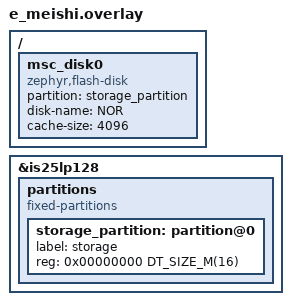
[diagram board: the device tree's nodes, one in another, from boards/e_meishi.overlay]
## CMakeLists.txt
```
cmake_minimum_required(VERSION 3.20.0)

find_package(Zephyr REQUIRED HINTS $ENV{ZEPHYR_BASE})
project(app)

target_sources(app PRIVATE
	src/main.c
	src/leds_pwm.c
	src/usb_msc.c
)
```

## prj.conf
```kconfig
CONFIG_MAIN_STACK_SIZE=2048

# Logging
CONFIG_LOG=y
CONFIG_USBD_LOG_LEVEL_WRN=y
CONFIG_UDC_DRIVER_LOG_LEVEL_WRN=y

# USB
CONFIG_USB_DEVICE_STACK_NEXT=y
CONFIG_USBD_MSC_CLASS=y
CONFIG_USBD_MSC_LUNS_PER_INSTANCE=1
# Serial number from the MCU unique ID (required by the MSC spec)
CONFIG_HWINFO=y

# Flash disk
CONFIG_FLASH=y
CONFIG_FLASH_MAP=y
CONFIG_FLASH_PAGE_LAYOUT=y
CONFIG_DISK_DRIVER_FLASH=y
```

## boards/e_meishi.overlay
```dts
/*
 * SPDX-FileCopyrightText: © 2026 Florian Vaussard
 * SPDX-License-Identifier: Apache-2.0
 */

/delete-node/ &storage_partition;

&is25lp128 {
	partitions {
		compatible = "fixed-partitions";
		#address-cells = <1>;
		#size-cells = <1>;

		storage_partition: partition@0 {
			label = "storage";
			reg = <0x00000000 DT_SIZE_M(16)>;
		};
	};
};

/ {
	msc_disk0 {
		compatible = "zephyr,flash-disk";
		partition = <&storage_partition>;
		disk-name = "NOR";
		cache-size = <4096>;
	};
};
```

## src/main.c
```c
#include <zephyr/kernel.h>

int main(void)
{
	printk("Zephyr e-meishi\n");

	while (true) {
		k_sleep(K_FOREVER);
	}

	return 0;
}
```

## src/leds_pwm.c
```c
/*
 * Module to play some trivial LED PWM animations
 *
 * Initially based on Zephyr's samples/drivers/led/pwm/:
 * - Copyright (c) 2020 Seagate Technology LLC
 *
 * SPDX-FileCopyrightText: © 2026 Florian Vaussard
 * SPDX-License-Identifier: Apache-2.0
 */

#include <zephyr/device.h>
#include <zephyr/devicetree.h>
#include <zephyr/drivers/led.h>
#include <zephyr/kernel.h>

#include <zephyr/logging/log.h>
LOG_MODULE_REGISTER(leds_pwm, CONFIG_LOG_DEFAULT_LEVEL);

#include "leds_pwm.h"

#define LED_PWM_NODE_ID		DT_COMPAT_GET_ANY_STATUS_OKAY(pwm_leds)
#define NUM_LEDS		DT_CHILD_NUM_STATUS_OKAY(LED_PWM_NODE_ID)

BUILD_ASSERT(NUM_LEDS > 0, "No PWM LEDs found");

/* Set the brightness of all the LEDs at the same time */
static int leds_all_set_brightness(const struct device *led_pwm, unsigned int level)
{
	int err;

	for (size_t i = 0; i < NUM_LEDS; i++) {
		err = led_set_brightness(led_pwm, i, level);
		if (err < 0) {
			LOG_ERR("err=%d", err);
			return err;
		}
	}

	return 0;
}

/* Ramp (up/down) the brightness of:
 * - All the LEDs if `led` is negative
 * - A specific LED otherwise
 */
static int leds_ramp(const struct device *led_pwm, bool on, int led, unsigned int ramp_duration_ms)
{
	const unsigned int ramp_step_ms = ramp_duration_ms / LED_BRIGHTNESS_MAX;
	int level;
	int err;

	if (ramp_step_ms == 0) {
		return -EINVAL;
	}
	if (led >= NUM_LEDS) {
		return -EINVAL;
	}

	if (on) {
		for (level = 0; level <= LED_BRIGHTNESS_MAX; level++) {
			if (led < 0) {
				err = leds_all_set_brightness(led_pwm, level);
			} else {
				err = led_set_brightness(led_pwm, led, level);
			}
			if (err < 0) {
				return err;
			}
			k_msleep(ramp_step_ms);
		}
	} else {
		for (level = LED_BRIGHTNESS_MAX; level >= 0; level--) {
			if (led < 0) {
				err = leds_all_set_brightness(led_pwm, level);
			} else {
				err = led_set_brightness(led_pwm, led, level);
			}
			if (err < 0) {
				return err;
			}
			k_msleep(ramp_step_ms);
		}
	}

	return 0;
}

int leds_ramp_all(const struct leds_pwm *leds, bool on, unsigned int ramp_duration_ms)
{
	return leds_ramp(leds->led_pwm, on, -1, ramp_duration_ms);
}

int leds_snake(const struct leds_pwm *leds, bool on, unsigned int led_ramp_ms, unsigned int snake_duration_ms)
{
	unsigned int leds_ramp_duration_ms;
	unsigned int snake_delay_ms;
	int err;

	if (led_ramp_ms == 0) {
		return -EINVAL;
	}
	if (NUM_LEDS <= 1) {
		return -EINVAL;
	}

	/* Total duration of the LED ramp-up/down */
	leds_ramp_duration_ms = (led_ramp_ms * NUM_LEDS);

	if (snake_duration_ms < leds_ramp_duration_ms) {
		/* Animation cannot last less than the total LED ramp-up/down */
		return -EINVAL;
	}

	/* Compute the delay between each LED */
	snake_delay_ms = (snake_duration_ms - leds_ramp_duration_ms) / (NUM_LEDS - 1);

	if (snake_delay_ms == 0) {
		return -EINVAL;
	}

	for (unsigned int led = 0; led < NUM_LEDS; led++) {
		err = leds_ramp(leds->led_pwm, on, led, led_ramp_ms);
		if (err) {
			return err;
		}

		if (led < NUM_LEDS - 1) {
			k_msleep(snake_delay_ms);
		}
	}

	return 0;
}

int leds_pwm_init(struct leds_pwm *leds)
{
	leds->led_pwm = DEVICE_DT_GET(LED_PWM_NODE_ID);
	if (!device_is_ready(leds->led_pwm)) {
		LOG_ERR("Device %s is not ready", leds->led_pwm->name);
		leds->led_pwm = NULL;
		return -ENODEV;
	}

	return 0;
}
```

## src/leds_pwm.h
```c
/*
 * SPDX-FileCopyrightText: © 2026 Florian Vaussard
 * SPDX-License-Identifier: Apache-2.0
 */

#ifndef MEISHI_LEDS_PWM_H
#define MEISHI_LEDS_PWM_H

#include <zephyr/device.h>

/**
 * @brief State of the PWM LEDs
 */
struct leds_pwm {
	/** PWM LED controller device, NULL if not available. */
	const struct device *led_pwm;
};

/**
 * @brief Initialize the PWM LEDs
 *
 * Retrieve the "pwm-leds" device from the devicetree and check that it is
 * ready. Having at least one LED is checked at build time.
 *
 * @param leds		LEDs state to initialize
 *
 * @retval 0 on success
 * @retval -ENODEV if the device is not ready
 */
int leds_pwm_init(struct leds_pwm *leds);

/**
 * @brief Ramp the brightness of all LEDs simultaneously
 *
 * The brightness is changed linearly from 0 to 100% (or from 100% to 0) in
 * steps of 1%. This function blocks until the ramp is complete.
 *
 * @param leds			LEDs state, as initialized by leds_pwm_init()
 * @param on			true to ramp up (turn on), false to ramp down (turn off)
 * @param ramp_duration_ms	Duration of the ramp, in milliseconds. Must be at
 *				least 100 ms (1 ms per brightness step)
 *
 * @retval 0 on success
 * @retval -EINVAL if @p ramp_duration_ms is too short
 * @retval <0 other negative errno code from the LED driver
 */
int leds_ramp_all(const struct leds_pwm *leds, bool on, unsigned int ramp_duration_ms);

/**
 * @brief Ramp the LEDs one after the other, in a snake-like animation
 *
 * Each LED is ramped up (or down) in turn, in devicetree order, with a delay
 * between consecutive LEDs computed so that the whole animation lasts
 * approximately @p snake_duration_ms. This function blocks until the
 * animation is complete.
 *
 * @param leds			LEDs state, as initialized by leds_pwm_init()
 * @param on			true to ramp up (turn on), false to ramp down (turn off)
 * @param led_ramp_ms		Duration of the ramp of a single LED, in milliseconds.
 *				Must be at least 100 ms (1 ms per brightness step)
 * @param snake_duration_ms	Total duration of the animation, in milliseconds.
 *				Must be long enough to fit all the individual LED ramps, plus a
 *				non-zero delay between them
 *
 * @retval 0 on success
 * @retval -EINVAL if there are less than 2 LEDs, or if the durations are invalid
 * @retval <0 other negative errno code from the LED driver
 */
int leds_snake(const struct leds_pwm *leds, bool on, unsigned int led_ramp_ms, unsigned int snake_duration_ms);

#endif /* MEISHI_LEDS_PWM_H */
```

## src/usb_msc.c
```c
/*
 * Based on Zephyr's samples/subsys/usb/mass:
 * - Copyright (c) 2016 Intel Corporation.
 * - Copyright (c) 2019-2020 Nordic Semiconductor ASA
 *
 * SPDX-FileCopyrightText: © 2026 Florian Vaussard
 * SPDX-License-Identifier: Apache-2.0
 */

#include <zephyr/kernel.h>
#include <zephyr/logging/log.h>
#include <zephyr/storage/disk_access.h>
#include <zephyr/usb/usbd.h>
#include <zephyr/usb/class/usbd_msc.h>

#include "usb_msc.h"

LOG_MODULE_REGISTER(usb_msc, CONFIG_LOG_DEFAULT_LEVEL);

/* VID / PID from Zephyr sample...
 * TODO: request a PID from https://pid.codes/
 */
#define USB_VID			0x2fe3
#define USB_PID			0x0008

#define VENDOR			"Vaussard"
#define PRODUCT			"e-meishi"

/* Worst case power scenario @85°C:
 * - STM32U3: 6.7mA (48MHz)
 * - IS25LP128: 20mA (during program / erase)
 * - APT1608: 7x 5mA
 *
 * Total: 61.7mA
 * Use 100mA to have some margin and count as a low-power device
 */
#define USBD_MAX_POWER		50 /* x 2mA = 100mA */

USBD_DEVICE_DEFINE(meishi_usbd,
		   DEVICE_DT_GET(DT_NODELABEL(zephyr_udc0)),
		   USB_VID, USB_PID);

USBD_DESC_LANG_DEFINE(meishi_lang);
USBD_DESC_MANUFACTURER_DEFINE(meishi_mfr, VENDOR);
USBD_DESC_PRODUCT_DEFINE(meishi_product, PRODUCT);
IF_ENABLED(CONFIG_HWINFO, (USBD_DESC_SERIAL_NUMBER_DEFINE(meishi_sn)));

USBD_DESC_CONFIG_DEFINE(fs_cfg_desc, "FS Configuration");

/* Full-speed only (STM32U3), bus-powered, no remote wakeup */
USBD_CONFIGURATION_DEFINE(meishi_fs_config,
			  0,
			  USBD_MAX_POWER, &fs_cfg_desc);

#define DISK_NAME	"NOR"

USBD_DEFINE_MSC_LUN(nor, DISK_NAME, VENDOR, PRODUCT, "0.00");

static int usb_init(void)
{
	int err;

	err = usbd_add_descriptor(&meishi_usbd, &meishi_lang);
	if (err) {
		LOG_ERR("Failed to initialize language descriptor (%d)", err);
		return err;
	}

	err = usbd_add_descriptor(&meishi_usbd, &meishi_mfr);
	if (err) {
		LOG_ERR("Failed to initialize manufacturer descriptor (%d)", err);
		return err;
	}

	err = usbd_add_descriptor(&meishi_usbd, &meishi_product);
	if (err) {
		LOG_ERR("Failed to initialize product descriptor (%d)", err);
		return err;
	}

#if defined(CONFIG_HWINFO)
	err = usbd_add_descriptor(&meishi_usbd, &meishi_sn);
	if (err) {
		LOG_ERR("Failed to initialize SN descriptor (%d)", err);
		return err;
	}
#endif

	err = usbd_add_configuration(&meishi_usbd, USBD_SPEED_FS,
				     &meishi_fs_config);
	if (err) {
		LOG_ERR("Failed to add Full-Speed configuration (%d)", err);
		return err;
	}

	err = usbd_register_all_classes(&meishi_usbd, USBD_SPEED_FS, 1, NULL);
	if (err) {
		LOG_ERR("Failed to register classes (%d)", err);
		return err;
	}

	/* Single-function device: class information is in the interface descriptor */
	usbd_device_set_code_triple(&meishi_usbd, USBD_SPEED_FS, 0, 0, 0);

	err = usbd_init(&meishi_usbd);
	if (err) {
		LOG_ERR("Failed to initialize device support (%d)", err);
		return err;
	}

	err = usbd_enable(&meishi_usbd);
	if (err) {
		LOG_ERR("Failed to enable device support (%d)", err);
		return err;
	}

	return 0;
}

int usb_msc_init(void)
{
	int err;

	/* Initialize the disk */
	err = disk_access_ioctl(DISK_NAME, DISK_IOCTL_CTRL_INIT, NULL);
	if (err != 0) {
		LOG_ERR("Failed to initialize %s disk: %d", DISK_NAME, err);
		return err;
	}

	/* Initialize USB MSC */
	err = usb_init();
	if (err) {
		return err;
	}

	LOG_INF("The device is put in USB mass storage mode");

	return 0;
}
```

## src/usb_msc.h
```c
/*
 * SPDX-FileCopyrightText: © 2026 Florian Vaussard
 * SPDX-License-Identifier: Apache-2.0
 */
#ifndef MEISHI_USB_MSC_H
#define MEISHI_USB_MSC_H

/**
 * @brief Initialize the Flash disk and the USB MSC device
 *
 * @return 0 on success
 * @return A negative errno on failure
 */
int usb_msc_init(void);

#endif /* MEISHI_USB_MSC_H */
```
